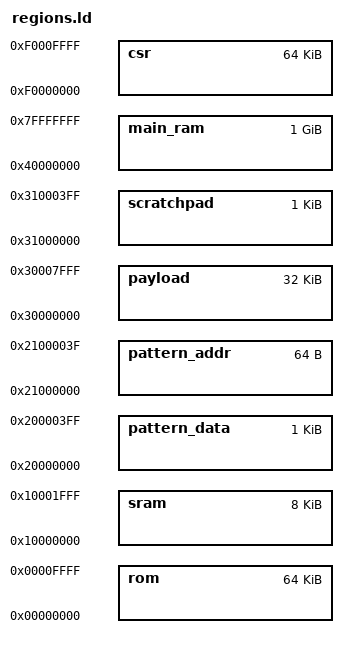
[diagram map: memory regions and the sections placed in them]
MEMORY {
	rom : ORIGIN = 0x00000000, LENGTH = 0x00010000
	sram : ORIGIN = 0x10000000, LENGTH = 0x00002000
	main_ram : ORIGIN = 0x40000000, LENGTH = 0x40000000
	pattern_data : ORIGIN = 0x20000000, LENGTH = 0x00000400
	pattern_addr : ORIGIN = 0x21000000, LENGTH = 0x00000040
	payload : ORIGIN = 0x30000000, LENGTH = 0x00008000
	scratchpad : ORIGIN = 0x31000000, LENGTH = 0x00000400
	csr : ORIGIN = 0xf0000000, LENGTH = 0x00010000
}
